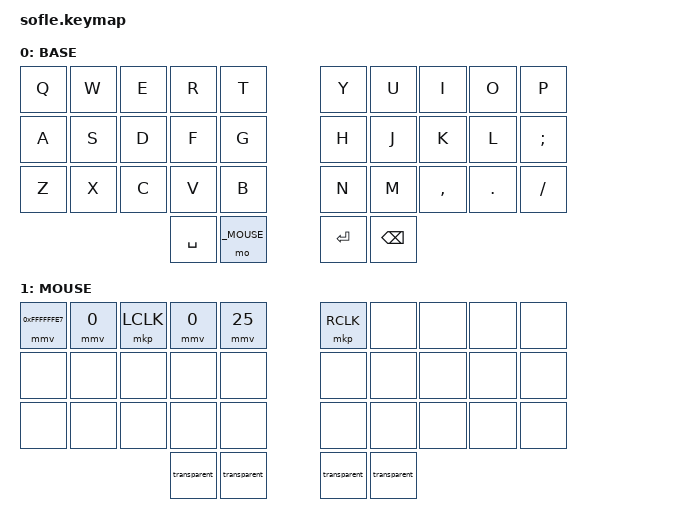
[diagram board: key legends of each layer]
/* FIRST: include the pointing helpers */
#include <dt-bindings/zmk/pointing.h>

 / {
    compatible = "zmk,keymap";

    /* layer indexes */
    #define _BASE   0
    #define _MOUSE  1

    keymap {
        compatible = "zmk,keymap";

        /* ── 0 · BASE ───────────────────────────────── */
        base_layer {
            label = "BASE";
            bindings = <
            /* Row 1 */ &kp Q &kp W &kp E &kp R &kp T      &kp Y &kp U &kp I &kp O &kp P
            /* Row 2 */ &kp A &kp S &kp D &kp F &kp G      &kp H &kp J &kp K &kp L &kp SEMI
            /* Row 3 */ &kp Z &kp X &kp C &kp V &kp B      &kp N &kp M &kp COMMA &kp DOT &kp SLASH
            /* Thumbs */              &kp SPACE  &mo _MOUSE   &kp ENTER  &kp BSPC
            >;
        };

        /* ── 1 · MOUSE ─────────────────────────────── */
        mouse_layer {
            label = "MOUSE";
            bindings = <
            /*  Cursor movement (±25)  |   Clicks  */
            &mmv         0xFFFFFFE7 0          /* ←  -25 ,  0  */
            &mmv         0           0xFFFFFFE7 /* ↑   0 , -25 */
            &mkp LCLK                           /* left-click  */
            &mmv         0          25          /* ↓   0 ,  25 */
            &mmv        25           0          /* →  25 ,  0  */
            &mkp RCLK                           /* right-click */
            /* remaining cells unused */
            &none &none &none &none
            /* rows 2-3 unused for now */
            &none &none &none &none &none   &none &none &none &none &none
            &none &none &none &none &none   &none &none &none &none &none
                              /* thumbs */  &transparent &transparent &transparent &transparent
            >;
        };
    };
 };
